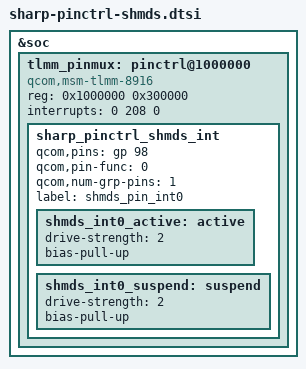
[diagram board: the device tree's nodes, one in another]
/* Copyright (c) 2013-2014, The Linux Foundation. All rights reserved.
 *
 * This program is free software; you can redistribute it and/or modify
 * it under the terms of the GNU General Public License version 2 and
 * only version 2 as published by the Free Software Foundation.
 *
 * This program is distributed in the hope that it will be useful,
 * but WITHOUT ANY WARRANTY; without even the implied warranty of
 * MERCHANTABILITY or FITNESS FOR A PARTICULAR PURPOSE.  See the
 * GNU General Public License for more details.
 */

&soc {
	tlmm_pinmux: pinctrl@1000000 {
		compatible = "qcom,msm-tlmm-8916";
		reg = <0x1000000 0x300000>;
		interrupts = <0 208 0>;

		/*****************************************/
		/*  pinctrl customize setting            */
		/*  SHMDS                                */
		/*****************************************/
		sharp_pinctrl_shmds_int{
			qcom,pins = <&gp 98>;
			qcom,pin-func = <0>;
			qcom,num-grp-pins = <1>;
			label = "shmds_pin_int0";
			shmds_int0_active: active {
				drive-strength = <2>;
				bias-pull-up;
			};
			shmds_int0_suspend: suspend {
				drive-strength = <2>;
				bias-pull-up;
			};
		};
	};
};
